# TLE9278 register map
Vendor: Infineon; File version: 0.1
TLE9278 Family
Registers are 8-bit, read-write, no defined reset value unless marked. A register's access mark holds for its fields unless they carry their own. Offsets are from the block's base; lines under a group give offsets from that group; [hi:lo] are bit positions; {n}, {i} and the like mark numbered series; 'fields as' and 'values as' point back to an identical list; <NAME> marks a mode.

## Memory map
0x00000000 CTRL size 0x40 — Control
0x00000040 STAT size 0x40 — Status

## CTRL — Control
Base 0x00000000
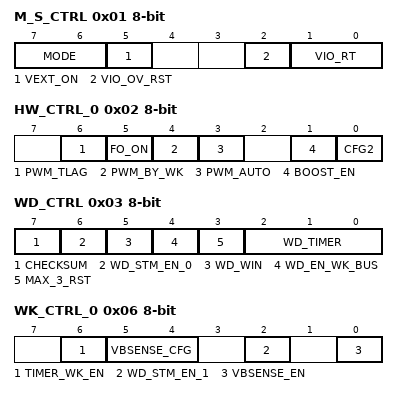
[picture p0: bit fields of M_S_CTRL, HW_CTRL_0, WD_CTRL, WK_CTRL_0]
0x01 M_S_CTRL — Mode- and Supply Control
  [7:6] MODE — SBC Mode Control
    0=Normal (SBC Normal Mode); 1=Sleep (SBC Sleep Mode); 2=Stop (SBC Stop Mode); 3=Soft_Reset (SBC Reset: Soft Reset is executed (configuration of RSTN triggering in bit SOFT_RESET_RST))
  [5] VEXT_ON — If PCFG is left open, VEXT Mode Control
    0=VEXT_off (VCC3 off); 1=VEXT_enabled (VCC3 is enabled (as independent voltage regulator))
  [2] VIO_OV_RST — VIO Over Voltage Reset / Fail-Safe enable
    0=no_SBC_restart (VIO_ OV is set in case of VIO_OV; no SBC Restart or Fail-Safe is entered for VIO_OV); 1=depending_on_configuration (VIO_ OV is set in case of VIO_OV; depending on the device configuration SBC Restart or SBC Fail-Safe Mode is entered(see );)
  [1:0] VIO_RT — VIO Reset Threshold Control
    0=Vrt1 selected (highest threshold); 1=Vrt2 selected; 2=Vrt3 selected; 3=Vrt4 selected
0x02 HW_CTRL_0 — Hardware Control 0
  [6] PWM_TLAG — PWM Lag time
    0=100μs; 1=1ms
  [5] FO_ON — Failure Output Activation
    0=off (FO not activated by software, FO can be activated by defined failure (0)); 1=on (FO activated by software (1))
  [4] PWM_BY_WK — PWM of Buck converter enabled by WK pin
    0=PFM (Buck converter uses PFM in SBC Stop Mode); 1=switched_between_PFM_and_PWM (1) (Buck converter can be switched between PFM and PWM by the WK pin in SBC Stop Mode)
  [3] PWM_AUTO — Automatic transition PFM-PWM in SBC Stop Mode
    0=VCC3_as_stanalone_regulator (0) (Buck converter always uses PFM in SBC Stop Mode (default)); 1=in_load_sharing_with_VCC1 (1) (Buck converter uses automatic transition PFM to PWM in case large current needed in SBC Stop Mode. To come back in PFM, write a SBC Stop Mode command to M_S_CTRL.)
  [1] BOOST_EN — Boost converter enable
    0=Boost_Off; 1=Boost enabled, automatic switch ON for LOW VS Voltage
  [0] CFG2 — Configuration Select 2
    0=after_2nd (Fail Output (FO) enabled after 2nd watchdog trigger fail Config 3/4); 1=after_1st (Fail Output (FO) enabled after 1st watchdog trigger fail Config 1/2)
0x03 WD_CTRL — Watchdog Control
  [7] CHECKSUM — Watchdog Setting Check Sum Bit
    0=Counts as 0 for checksum calculation; 1=Counts as 1 for checksum calculation
  [6] WD_STM_EN_0 — Watchdog Deactivation during SBC Stop Mode, bit 0
    0=active (Watchdog is active in Stop Mode); 1=deactivated (Watchdog is deactivated in Stop Mode)
  [5] WD_WIN — Watchdog Type Selection
    0=Time-out (Watchdog works as a Time-Out watchdog); 1=Window (Watchdog works as a Window watchdog)
  [4] WD_EN_WK_BUS — Watchdog Enable after Bus (CAN) Wake in SBC Stop Mode
    0=off (Watchdog will not start after a CAN wake); 1=on (Watchdog starts with a long open window after CANx Wake)
  [3] MAX_3_RST — Limit number of resets due to a Watchdog failure
    0=always_reset (Always generate a reset in case of WD fail); 1=after_3_consecutive_resets (1) (After 3 consecutive resets due to WD fail, no further reset is generated (only valid in config 1/3))
  [2:0] WD_TIMER — Watchdog Timer Period
    0=10ms; 1=20ms; 2=50ms; 3=100ms; 4=200ms; 5=500ms; 6=1s (1000ms)
0x04 BUS_CTRL_0 — Bus Control
  [2:0] CAN0 — HS-CAN Module Modes
    0=off (CAN OFF); 1=wake_capable (CAN is wake capable (no SWK)); 2=receive_only (CAN Receive Only Mode (no SWK)); 3=normal (CAN Normal Mode (no SWK)); 4=off (CAN OFF); 5=wake_capable_(SWK) (CAN is wake capable with SWK); 6=receive_only_(SWK) (CAN Receive Only Mode with SWK); 7=normal_(SWK) (CAN Normal Mode with SWK)
0x06 WK_CTRL_0 — Internal Wake Input Control
  [6] TIMER_WK_EN — Wake Source Control (for cyclic wake)
    0=disabled (Cyclic wake disabled); 1=enabled (Cyclic wake enabled as a wake source)
  [5:4] VBSENSE_CFG — Battery Voltage Monitoring Threshold Selection
    0=VBSENSE0 threshold selected (highest threshold); 1=VBSENSE1 threshold selected; 2=VBSENSE2 threshold selected; 3=VBSENSE3 threshold selected
  [2] WD_STM_EN_1 — Watchdog Deactivation during Stop Mode, bit 1 ()
    0=WD_active_in_stop_mode (Watchdog is active in Stop Mode); 1=off (1) (Watchdog is deactivated in Stop Mode)
  [0] VBSENSE_EN — Enable the fast battery voltage monitoring
    0=fast_VB_disabled (Fast Vbatt Monitoring disabled); 1=fast_VB_disabled (Fast Vbatt Monitoring enabled)
0x07 WK_CTRL_1 — External Wake Source Control
  [0] WK_EN — WK Wake Source Control
    0=disabled (WK wake disabled); 1=enabled (WK is enabled as a wake source)
0x08 WK_PUPD_CTRL — Wake Input Level Control
  [1:0] WK_PUPD — WK Pull-Up / Pull-Down Configuration
    0=none (No pull-up / pull-down selected); 1=Pull-down resistor selected; 2=none (Pull-up resistor selected); 3=pull-down (Automatic switching to pull-up or pull-down)
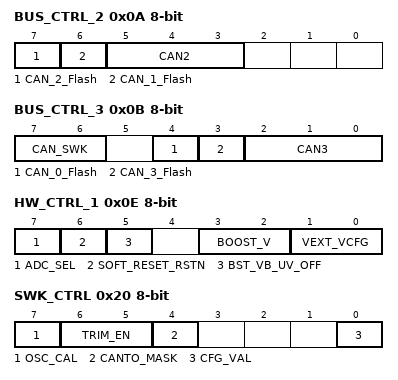
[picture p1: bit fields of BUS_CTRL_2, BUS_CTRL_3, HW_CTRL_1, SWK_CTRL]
0x0A BUS_CTRL_2 — Bus Control 0
  [7] CAN_2_Flash — CAN2 Flash Mode activation
    0=disabled (Flash Mode disabled: CAN communication up to 5MBaud); 1=enabled (Flash Mode enabled: CAN communication for higher than 5MBaud (higher emission on CAN bus - no slew rate control))
  [6] CAN_1_Flash — CAN1 Flash Mode activation
    values as CAN_2_Flash
  [5:3] CAN2 — HS-CAN_2 Module Modes
    0=OFF (CAN OFF); 1=wake_capable (no SWK) (CAN is wake capable (no SWK)); 2=receive_only (CAN Receive Only Mode (no SWK)); 3=normal (CAN Normal Mode (no SWK)); 4=off (CAN OFF); 5=wake_capable_(SWK) (CAN is wake capable with SWK); 6=receive_only_(SWK) (CAN Receive Only Mode with SWK); 7=normal_(SWK) (CAN Normal Mode with SWK)
0x0B BUS_CTRL_3 — Bus Control 3
  [7:6] CAN_SWK — Banking Control for CAN Selective Wake Configurations
    {v}=CAN{v} (CAN{v} Module) (v=0..3)
  [4] CAN_0_Flash — CAN0 Flash Mode activation
    values as BUS_CTRL_2.CAN_2_Flash
  [3] CAN_3_Flash — CAN3 Flash Mode activation
    values as BUS_CTRL_2.CAN_2_Flash
  [2:0] CAN3 — HS-CAN_3 Module Modes
    values as BUS_CTRL_2.CAN2
0x0C TIMER_CTRL_0 — Timer_0 Control and Selection
  [2:0] TIMER_0_PER — Cyclic Wake Period Configuration
    0=10ms; 1=20ms; 2=50ms; 3=100ms; 4=200ms; 5=1s; 6=2s
0x0E HW_CTRL_1 — Hardware Control 1
  [7] ADC_SEL — 8 bit ADC input channel selector
    0=WK (WK pin is selected); 1=VBSENSE (VBSENSE pin is selected)
  [6] SOFT_RESET_RSTN — Soft Reset Configuration
    0=triggered (RSTN will be triggered (pulled low) during a Software Reset (default)); 1=no_triggering (No RSTN triggering during a Software Reset)
  [5] BST_VB_UV_OFF — Boost switch-off control on VBSENSE low voltage condition
    0=disable (Boost automatic switch-off disable); 1=enable (Boost automatic switch-off enable)
  [3:2] BOOST_V — BOOST Output voltage configuration
    0=6.7V (6.7V output (default)); 1=8V (8V output); 2=10V (10V output); 3=12V (12V output)
  [1:0] VEXT_VCFG — VEXT Output voltage configuration
    0=5.0V (5.0V output); 1=3.3V (3.3V output (default)); 2=1.8V (1.8V output); 3=1.2V (1.2V output)
0x1E SYS_STAT_CTRL — System Status Control
  [7:0] SYS_STAT — System Status Control Byte (bit0=LSB; bit7=MSB) Dedicated byte for system configuration, access only by microcontroller
0x20 SWK_CTRL — CAN Selective Wake Control
  [7] OSC_CAL — Oscillator Calibration Mode
    0=disabled (Oscillator Calibration is disabled); 1=enabled (Oscillator Calibration is enabled)
  [6:5] TRIM_EN — (Un)locking mechanism of oscillator recalibration
    0=locked_0; 1=locked_1; 2=locked_2; 3=unlocked
  [4] CANTO_MASK — CAN Time Out Masking
    0=no_INTN (CAN time-out is masked - no interrupt (on pin INTN) is triggered); 1=INTN (CAN time-out is signaled on INTN)
  [0] CFG_VAL — SWK Configuration valid
    0=not_valid (Configuration is not valid (SWK not possible)); 1=valid (SWK configuration valid, needs to be set to enable SWK)
0x21 SWK_BTL1_CTRL — SWK Bit Timing Logic Control1
  [7:0] TBIT — Number of Time Quanta in a Bit Time
0x22 SWK_BTL2_CTRL — SWK Bit Timing Control2
  [5:0] SP — Sampling Point Position
0x23 SWK_ID3_CTRL — SWK WUF Identifier bits 28...21
  [7:0] ID28_21 — WUF Identifier Bits 28...21
0x24 SWK_ID2_CTRL — SWK WUF Identifier bits 20...13
  [7:0] ID20_13 — WUF Identifier Bits 20...13
0x25 SWK_ID1_CTRL — SWK WUF Identifier bits 12...5
  [7:0] ID12_5 — WUF Identifier Bits 12...5
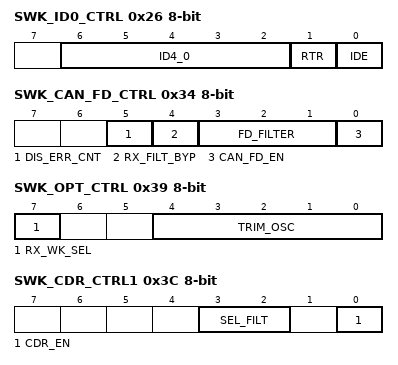
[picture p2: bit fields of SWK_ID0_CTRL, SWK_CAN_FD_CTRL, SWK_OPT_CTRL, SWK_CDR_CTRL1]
0x26 SWK_ID0_CTRL — SWK WUF Identifier bits 4...0
  [6:2] ID4_0 — WUF Identifier Bits 4..0
  [1] RTR — Remote Transmission Request Field (acc. ISO 11898-1)
    0=disabled (Normal Data Frame); 1=enabled (Remote Transmission Request)
  [0] IDE — Identifier Extension Bit
    0=11bit (Standard Identifier Length (11 bit)); 1=29bit (Extended Identifier Length (29 bit))
0x27 SWK_MASK_ID3_CTRL — SWK WUF Identifier Mask bits 28...21
  [7:0] MASK_ID28_21 — WUF Identifier Mask Bits 28...21
    0=ignored (Unmasked - bit is ignored); 1=enabled (Masked - bit is compared in CAN frame)
0x28 SWK_MASK_ID2_CTRL — SWK WUF Identifier Mask bits 20...13
  [7:0] MASK_ID20_13 — WUF Identifier Mask Bits 20...13
    0=ignored (0) (Unmasked - bit is ignored); 1=enabled (1) (Masked - bit is compared in CAN frame)
0x29 SWK_MASK_ID1_CTRL — SWK WUF Identifier Mask bits 12...5
  [7:0] MASK_ID12_5 — WUF Identifier Mask Bits 12...5
    values as SWK_MASK_ID3_CTRL.MASK_ID28_21
0x2A SWK_MASK_ID0_CTRL — SWK WUF Identifier bits 4...0
  [6:2] MASK_ID4_0 — WUF Identifier MASK Bits 4..0
    0=irgnored (Unmasked - bit is ignored); 1=enabled (Masked - bit is compared in CAN frame)
0x2B SWK_DLC_CTRL — SWK Frame Data Length Code Control
  [3:0] DLC — Payload length in number of bytes
    0=Frame Data Length = 0 or cleared; {v}=Frame Data Length = {v} (v=1..8)
0x2C SWK_DATA7_CTRL — SWK Data7 Register
  [7:0] DATA7 — Data7 byte content(bit0=LSB; bit7=MSB)
0x2D SWK_DATA6_CTRL — SWK Data6 Register
  [7:0] DATA6 — Data6 byte content (bit0=LSB; bit7=MSB)
0x2E SWK_DATA5_CTRL — SWK Data5 Register
  [7:0] DATA5 — Data5 byte content (bit0=LSB; bit7=MSB)
0x2F SWK_DATA4_CTRL — SWK Data4 Register
  [7:0] DATA4 — Data4 byte content (bit0=LSB; bit7=MSB)
0x30 SWK_DATA3_CTRL — SWK Data3 Register
  [7:0] DATA3 — Data3 byte content (bit0=LSB; bit7=MSB)
0x31 SWK_DATA2_CTRL — SWK Data2 Register
  [7:0] DATA2 — Data2 byte content (bit0=LSB; bit7=MSB)
0x32 SWK_DATA1_CTRL — SWK Data1 Register
  [7:0] DATA1 — Data1 byte content (bit0=LSB; bit7=MSB)
0x33 SWK_DATA0_CTRL — SWK Data0 Register
  [7:0] DATA0 — Data0 byte content (bit0=LSB; bit7=MSB)
0x34 SWK_CAN_FD_CTRL — CAN FD Configuration Control Register
  [5] DIS_ERR_CNT — Error Counter Disable Function
    0=counter_enabled (Error Counter is enabled during SWK); 1=counter_disabled (Error counter is disabled during SWK only if CAN_FD_EN = ‘1')
  [4] RX_FILT_BYP — RX Receiver Filter Bypass
    0=disabled (RX Filter not bypassed); 1=enabled (RX Filter bypassed)
  [3:1] FD_FILTER — CAN FD Dominant Filter Time
    0=50ns; 1=100ns; 2=150ns; 3=200ns; 4=250ns; 5=300ns; 6=350ns; 7=700ns
  [0] CAN_FD_EN — CAN FD Tolerant Mode
    0=disabled (CAN FD Tolerant Mode disabled); 1=enabled (CAN FD Tolerant Mode enabled)
0x38 SWK_OSC_TRIM_CTRL — SWK Oscillator Trimming Register
  [7:0] TRIM_OSC — Oscillator trimming (bit0=LSB; bit7=MSB); (only writable if TRIM_EN = ‘11')
0x39 SWK_OPT_CTRL — Selective Wake Options Register
  [7] RX_WK_SEL — SWK Receiver selection (only accessible if TRIM_EN = ‘11')
    0=Low-Power Receiver selected during SWK; 1=Standard Receiver selected during SWK
  [4:0] TRIM_OSC — Oscillator trimming (bit8=LSB; bit12=MSB); (only writable if TRIM_EN = ‘11')
0x3A SWK_OSC_CAL_H_STAT ro — SWK Oscillator Calibration High Register
  [7:0] OSC_CAL_H — Oscillator Calibration High Register
0x3B SWK_OSC_CAL_L_STAT ro — SWK Oscillator Calibration Low Register
  [7:0] OSC_CAL_L — Oscillator Calibration Low Register
0x3C SWK_CDR_CTRL1 — CDR Control 1 Register
  [3:2] SEL_FILT — Select Time Constant of Filter
    0=Time constant 8; 1=16(default) (Time constant 16 (default)); 2=Time constant 32; 3=adaptive (adapt distance between falling edges 2, 3 bit: Time constant 32 distance between f. edges 4, 5, 6, 7, 8 bit: Time constant 16 distance between falling edges 9, 10 bit: Time constant 8)
  [0] CDR_EN — Enable CDR
    0=disabled (CDR disabled); 1=enabled (CDR enabled)
0x3D SWK_CDR_CTRL2 — CDR Control 2Register
  [1:0] SEL_OSC_CLK — Input Frequency for CDR module
0x3E SWK_CDR_LIMIT_HIGH_CTRL — SWK CDR Upper Limit Control
  [7:0] CDR_LIM_H — Upper Bit Time Detection Range of Clock and Data Recovery
0x3F SWK_CDR_LIMIT_LOW_CTRL — SWK CDR Lower Limit Control
  [7:0] CDR_LIM_L — Lower Bit Time Detection Range of Clock and Data Recovery
